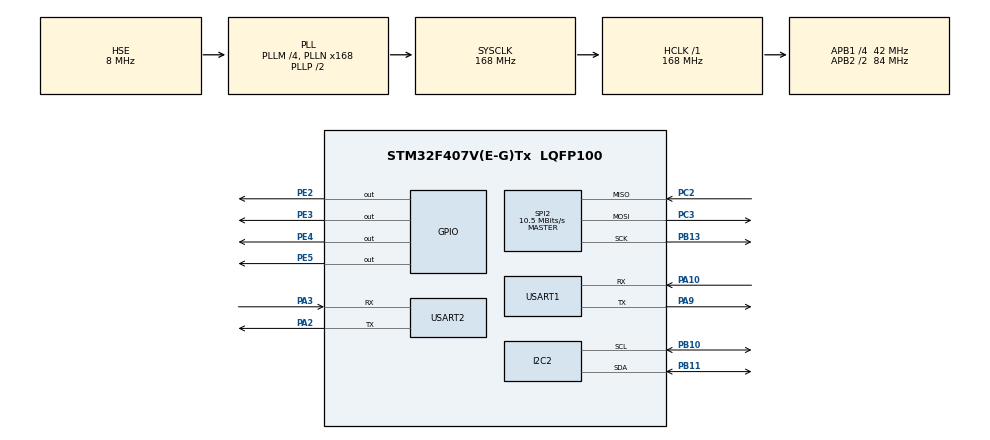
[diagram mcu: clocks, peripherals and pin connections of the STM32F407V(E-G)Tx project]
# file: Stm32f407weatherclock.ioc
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Mcu.Family=STM32F4
Mcu.Name=STM32F407V(E-G)Tx
Mcu.Package=LQFP100
NVIC.PriorityGroup=NVIC_PRIORITYGROUP_4
NVIC.TIM2_IRQn=true\:0\:0\:false\:false\:true\:true\:true\:true
PA10.Mode=Asynchronous
PA10.Signal=USART1_RX
PA2.GPIO_Speed=GPIO_SPEED_FREQ_HIGH
PA2.Mode=Asynchronous
PA2.Signal=USART2_TX
PA3.GPIO_Speed=GPIO_SPEED_FREQ_HIGH
PA3.Mode=Asynchronous
PA3.Signal=USART2_RX
PA9.Mode=Asynchronous
PA9.Signal=USART1_TX
PB10.Mode=I2C
PB10.Signal=I2C2_SCL
PB11.Mode=I2C
PB11.Signal=I2C2_SDA
PB13.Mode=Full_Duplex_Master
PB13.Signal=SPI2_SCK
PC14-OSC32_IN.Mode=LSE-External-Oscillator
PC14-OSC32_IN.Signal=RCC_OSC32_IN
PC15-OSC32_OUT.Mode=LSE-External-Oscillator
PC15-OSC32_OUT.Signal=RCC_OSC32_OUT
PC2.Mode=Full_Duplex_Master
PC2.Signal=SPI2_MISO
PC3.Mode=Full_Duplex_Master
PC3.Signal=SPI2_MOSI
PE2.GPIO_ModeDefaultOutputPP=GPIO_MODE_OUTPUT_PP
PE2.GPIO_PuPd=GPIO_NOPULL
PE2.GPIO_Speed=GPIO_SPEED_FREQ_HIGH
PE2.PinState=GPIO_PIN_SET
PE2.Signal=GPIO_Output
PE3.GPIO_ModeDefaultOutputPP=GPIO_MODE_OUTPUT_PP
PE3.GPIO_PuPd=GPIO_NOPULL
PE3.GPIO_Speed=GPIO_SPEED_FREQ_HIGH
PE3.PinState=GPIO_PIN_SET
PE3.Signal=GPIO_Output
PE4.GPIO_ModeDefaultOutputPP=GPIO_MODE_OUTPUT_PP
PE4.GPIO_PuPd=GPIO_NOPULL
PE4.GPIO_Speed=GPIO_SPEED_FREQ_HIGH
PE4.PinState=GPIO_PIN_SET
PE4.Signal=GPIO_Output
PE5.GPIO_ModeDefaultOutputPP=GPIO_MODE_OUTPUT_PP
PE5.GPIO_PuPd=GPIO_NOPULL
PE5.GPIO_Speed=GPIO_SPEED_FREQ_HIGH
PE5.PinState=GPIO_PIN_RESET
PE5.Signal=GPIO_Output
PH0-OSC_IN.Mode=HSE-External-Oscillator
PH0-OSC_IN.Signal=RCC_OSC_IN
PH1-OSC_OUT.Mode=HSE-External-Oscillator
PH1-OSC_OUT.Signal=RCC_OSC_OUT
ProjectManager.HeapSize=0x200
ProjectManager.StackSize=0x400
ProjectManager.TargetToolchain=MDK-ARM V5.32
RCC.48MHZClocksFreq_Value=84000000
RCC.AHBFreq_Value=168000000
RCC.APB1CLKDivider=RCC_HCLK_DIV4
RCC.APB1Freq_Value=42000000
RCC.APB1TimFreq_Value=84000000
RCC.APB2CLKDivider=RCC_HCLK_DIV2
RCC.APB2Freq_Value=84000000
RCC.APB2TimFreq_Value=168000000
RCC.CortexFreq_Value=168000000
RCC.HCLKFreq_Value=168000000
RCC.HSE_VALUE=8000000
RCC.HSI_VALUE=16000000
RCC.PLLM=4
RCC.PLLN=168
RCC.PLLSourceVirtual=RCC_PLLSOURCE_HSE
RCC.RCC_RTC_Clock_Source=RCC_RTCCLKSOURCE_LSE
RCC.RCC_RTC_Clock_SourceVirtual=RCC_RTCCLKSOURCE_LSE
RCC.SYSCLKFreq_VALUE=168000000
RCC.SYSCLKSource=RCC_SYSCLKSOURCE_PLLCLK
RCC.VCOOutputFreq_Value=336000000
RTC.Format=RTC_FORMAT_BIN
SPI2.BaudRatePrescaler=SPI_BAUDRATEPRESCALER_4
SPI2.CalculateBaudRate=10.5 MBits/s
SPI2.Direction=SPI_DIRECTION_2LINES
SPI2.Mode=SPI_MODE_MASTER
SPI2.VirtualType=VM_MASTER
TIM2.AutoReloadPreload=TIM_AUTORELOAD_PRELOAD_ENABLE
TIM2.Period=999
TIM2.Prescaler=83
USART1.VirtualMode=VM_ASYNC
USART2.VirtualMode=VM_ASYNC
VP_RTC_VS_RTC_Activate.Mode=RTC_Enabled
VP_RTC_VS_RTC_Calendar.Mode=RTC_Calendar
VP_TIM2_VS_ClockSourceINT.Mode=Internal
board=custom

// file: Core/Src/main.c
/* USER CODE BEGIN Header */
/**
  ******************************************************************************
  * @file           : main.c
  * @brief          : Main program body
  ******************************************************************************
  * @attention
  *
  * Copyright (c) 2026 STMicroelectronics.
  * All rights reserved.
  *
  * This software is licensed under terms that can be found in the LICENSE file
  * in the root directory of this software component.
  * If no LICENSE file comes with this software, it is provided AS-IS.
  *
  ******************************************************************************
  */
/* USER CODE END Header */
#include "main.h"
#include "i2c.h"
#include "rtc.h"
#include "spi.h"
#include "tim.h"
#include "usart.h"
#include "gpio.h"

/* USER CODE BEGIN Includes */
#include "headfile.h"
#include "st7789.h"

/* USER CODE END Includes */

void SystemClock_Config(void);

int main(void)
{

  /* MCU Configuration--------------------------------------------------------*/

  /* Reset of all peripherals, Initializes the Flash interface and the Systick. */
  HAL_Init();

  /* Configure the system clock */
  SystemClock_Config();

  /* Initialize all configured peripherals */
  MX_GPIO_Init();
  MX_SPI2_Init();
  MX_I2C2_Init();
  MX_USART1_UART_Init();
  MX_USART2_UART_Init();
  MX_RTC_Init();
  MX_TIM2_Init();
  /* USER CODE BEGIN 2 */

	HAL_TIM_Base_Start_IT(&htim2);

	aht20_init();
	st7789_init_display();

	welcome_page_display();

	wifi_init();
  wifi_page_display();
	wifi_wait_connect();

  main_loop_init();
	main_page_display();

//	aht20_init();
//	float temperature, humidity;

  /* USER CODE END 2 */

  /* Infinite loop */
  /* USER CODE BEGIN WHILE */
  while (1)
  {
		main_loop();

    /* USER CODE END WHILE */

  }
}

void SystemClock_Config(void)
{
  RCC_OscInitTypeDef RCC_OscInitStruct = {0};
  RCC_ClkInitTypeDef RCC_ClkInitStruct = {0};

  /** Configure the main internal regulator output voltage
  */
  __HAL_RCC_PWR_CLK_ENABLE();
  __HAL_PWR_VOLTAGESCALING_CONFIG(PWR_REGULATOR_VOLTAGE_SCALE1);

  /** Initializes the RCC Oscillators according to the specified parameters
  * in the RCC_OscInitTypeDef structure.
  */
  RCC_OscInitStruct.OscillatorType = RCC_OSCILLATORTYPE_HSE|RCC_OSCILLATORTYPE_LSE;
  RCC_OscInitStruct.HSEState = RCC_HSE_ON;
  RCC_OscInitStruct.LSEState = RCC_LSE_ON;
  RCC_OscInitStruct.PLL.PLLState = RCC_PLL_ON;
  RCC_OscInitStruct.PLL.PLLSource = RCC_PLLSOURCE_HSE;
  RCC_OscInitStruct.PLL.PLLM = 4;
  RCC_OscInitStruct.PLL.PLLN = 168;
  RCC_OscInitStruct.PLL.PLLP = RCC_PLLP_DIV2;
  RCC_OscInitStruct.PLL.PLLQ = 4;
  if (HAL_RCC_OscConfig(&RCC_OscInitStruct) != HAL_OK)
  {
    Error_Handler();
  }

  /** Initializes the CPU, AHB and APB buses clocks
  */
  RCC_ClkInitStruct.ClockType = RCC_CLOCKTYPE_HCLK|RCC_CLOCKTYPE_SYSCLK
                              |RCC_CLOCKTYPE_PCLK1|RCC_CLOCKTYPE_PCLK2;
  RCC_ClkInitStruct.SYSCLKSource = RCC_SYSCLKSOURCE_PLLCLK;
  RCC_ClkInitStruct.AHBCLKDivider = RCC_SYSCLK_DIV1;
  RCC_ClkInitStruct.APB1CLKDivider = RCC_HCLK_DIV4;
  RCC_ClkInitStruct.APB2CLKDivider = RCC_HCLK_DIV2;

  if (HAL_RCC_ClockConfig(&RCC_ClkInitStruct, FLASH_LATENCY_5) != HAL_OK)
  {
    Error_Handler();
  }
}

void Error_Handler(void)
{
  __disable_irq();
  while (1)
  {
  }
}
